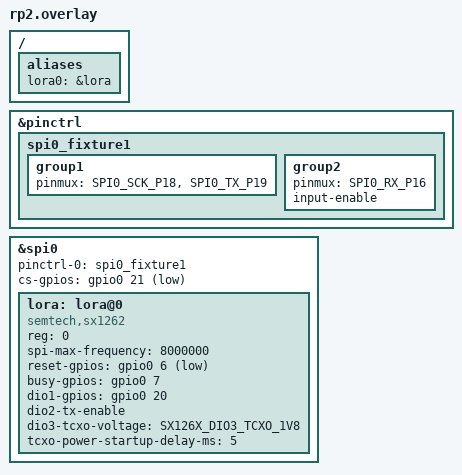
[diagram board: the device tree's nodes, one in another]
/* SPDX-License-Identifier: Apache-2.0 OR MIT */

#include <zephyr/dt-bindings/gpio/gpio.h>
#include <zephyr/dt-bindings/lora/sx126x.h>

/ {
	aliases {
		lora0 = &lora;
	};
};

&pinctrl {
	spi0_fixture1: spi0_fixture1 {
		group1 {
			pinmux = <SPI0_SCK_P18>, <SPI0_TX_P19>;
		};
		group2 {
			pinmux = <SPI0_RX_P16>;
			input-enable;
		};
	};
};

/*
 * A GPIO chip select: the drivers clock a command header and its data as
 * two buffers of one transfer, and the PL022's own chip select would drop
 * between them. The radio's other lines: NRESET GP6, BUSY GP7, DIO1 GP20.
 */
&spi0 {
	status = "okay";
	pinctrl-0 = <&spi0_fixture1>;
	pinctrl-names = "default";
	cs-gpios = <&gpio0 21 GPIO_ACTIVE_LOW>;

	lora: lora@0 {
		compatible = "semtech,sx1262";
		reg = <0>;
		spi-max-frequency = <8000000>;
		reset-gpios = <&gpio0 6 GPIO_ACTIVE_LOW>;
		busy-gpios = <&gpio0 7 GPIO_ACTIVE_HIGH>;
		dio1-gpios = <&gpio0 20 GPIO_ACTIVE_HIGH>;
		dio2-tx-enable;
		dio3-tcxo-voltage = <SX126X_DIO3_TCXO_1V8>;
		tcxo-power-startup-delay-ms = <5>;
		status = "okay";
	};
};
